# TM4C1294NCPDT register map
Vendor: Texas Instruments; File version: 2.2.0.295
CPU: CM4 r0p1, little endian, MPU, FPU, 3 interrupt priority bits
Registers are 32-bit, read-write, no defined reset value unless marked. A register's access mark holds for its fields unless they carry their own. Offsets are from the block's base; [hi:lo] are bit positions; {n}, {i} and the like mark numbered series; 'fields as' and 'values as' point back to an identical list.

## EPI0 — External Peripheral Interface (EPI0)
Base 0x400D0000
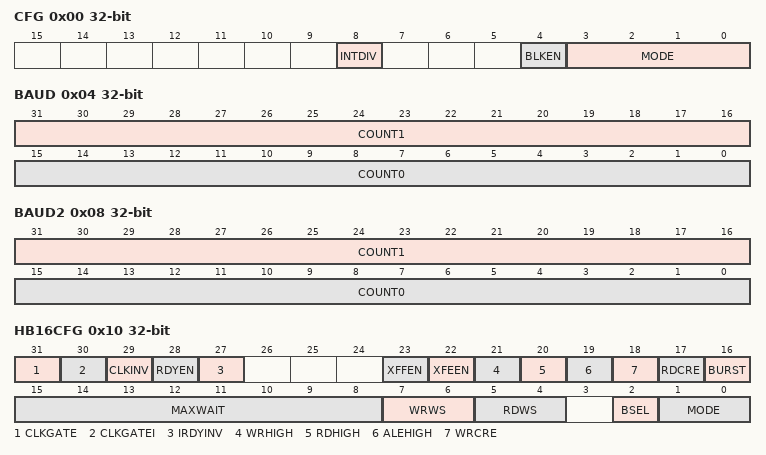
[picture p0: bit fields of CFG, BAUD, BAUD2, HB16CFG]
0x00 CFG
  [8] INTDIV — Integer Clock Divider Enable
  [4] BLKEN — Block Enable
  [3:0] MODE — Mode Select
    0=NONE (General Purpose); 1=SDRAM; 2=HB8 (8-Bit Host-Bus (HB8)); 3=HB16 (16-Bit Host-Bus (HB16))
0x04 BAUD
  [31:16] COUNT1 — Baud Rate Counter 1
  [15:0] COUNT0 — Baud Rate Counter 0
0x08 BAUD2
  [31:16] COUNT1 — CS3n Baud Rate Counter 1
  [15:0] COUNT0 — CS2n Baud Rate Counter 0
0x10 HB16CFG
  [31] CLKGATE — Clock Gated
  [30] CLKGATEI — Clock Gated Idle
  [29] CLKINV — Invert Output Clock Enable
  [28] RDYEN — Input Ready Enable
  [27] IRDYINV — Input Ready Invert
  [23] XFFEN — External FIFO FULL Enable
  [22] XFEEN — External FIFO EMPTY Enable
  [21] WRHIGH — WRITE Strobe Polarity
  [20] RDHIGH — READ Strobe Polarity
  [19] ALEHIGH — ALE Strobe Polarity
  [18] WRCRE — PSRAM Configuration Register
  [17] RDCRE — PSRAM Configuration Register
  [16] BURST — Burst Mode
  [15:8] MAXWAIT — Maximum Wait
  [7:6] WRWS — Write Wait States
    0=Active WRn is 2 EPI clocks; 1=Active WRn is 4 EPI clocks; 2=Active WRn is 6 EPI clocks; 3=Active WRn is 8 EPI clocks
  [5:4] RDWS — Read Wait States
    0=Active RDn is 2 EPI clocks; 1=Active RDn is 4 EPI clocks; 2=Active RDn is 6 EPI clocks; 3=Active RDn is 8 EPI clocks
  [2] BSEL — Byte Select Configuration
  [1:0] MODE — Host Bus Sub-Mode
    0=ADMUX (ADMUX - AD[15:0]); 1=ADNMUX (ADNONMUX - D[15:0]); 2=SRAM (Continuous Read - D[15:0]); 3=XFIFO (XFIFO - D[15:0])
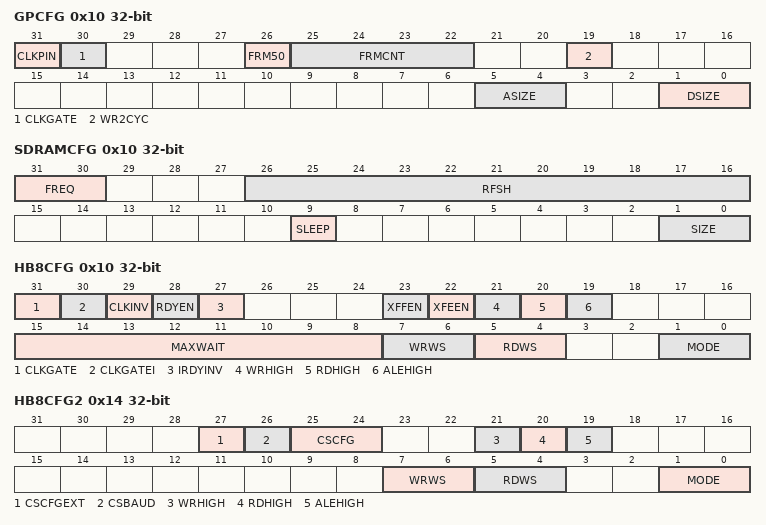
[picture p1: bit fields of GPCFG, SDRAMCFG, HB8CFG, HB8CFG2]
0x10 GPCFG
  [31] CLKPIN — Clock Pin
  [30] CLKGATE — Clock Gated
  [26] FRM50 — 50/50 Frame
  [25:22] FRMCNT — Frame Count
  [19] WR2CYC — 2-Cycle Writes
  [5:4] ASIZE — Address Bus Size
    0=NONE (No address); 1=4BIT (Up to 4 bits wide); 2=12BIT (Up to 12 bits wide. This size); 3=20BIT (Up to 20 bits wide. This size)
  [1:0] DSIZE — Size of Data Bus
    0=4BIT (8 Bits Wide (EPI0S0 to EPI0S7)); 1=16BIT (16 Bits Wide (EPI0S0 to EPI0S15)); 2=24BIT (24 Bits Wide (EPI0S0 to EPI0S23)); 3=32BIT (32 Bits Wide (EPI0S0 to EPI0S31))
0x10 SDRAMCFG
  [31:30] FREQ — EPI Frequency Range
    0=NONE (0 - 15 MHz); 1=15MHZ (15 - 30 MHz); 2=30MHZ (30 - 50 MHz)
  [26:16] RFSH — Refresh Counter
  [9] SLEEP — Sleep Mode
  [1:0] SIZE — Size of SDRAM
    0=8MB (64 megabits (8MB)); 1=16MB (128 megabits (16MB)); 2=32MB (256 megabits (32MB)); 3=64MB (512 megabits (64MB))
0x10 HB8CFG
  [31] CLKGATE — Clock Gated
  [30] CLKGATEI — Clock Gated when Idle
  [29] CLKINV — Invert Output Clock Enable
  [28] RDYEN — Input Ready Enable
  [27] IRDYINV — Input Ready Invert
  [23] XFFEN — External FIFO FULL Enable
  [22] XFEEN — External FIFO EMPTY Enable
  [21] WRHIGH — WRITE Strobe Polarity
  [20] RDHIGH — READ Strobe Polarity
  [19] ALEHIGH — ALE Strobe Polarity
  [15:8] MAXWAIT — Maximum Wait
  [7:6] WRWS — Write Wait States
    values as HB16CFG.WRWS
  [5:4] RDWS — Read Wait States
    values as HB16CFG.RDWS
  [1:0] MODE — Host Bus Sub-Mode
    0=MUX (ADMUX - AD[7:0]); 1=NMUX (ADNONMUX - D[7:0]); 2=SRAM (Continuous Read - D[7:0]); 3=FIFO (XFIFO - D[7:0])
0x14 HB8CFG2
  [27] CSCFGEXT — Chip Select Extended
  [26] CSBAUD — Chip Select Baud Rate and
  [25:24] CSCFG — Chip Select Configuration
    0=ALE (ALE Configuration); 1=CS (CSn Configuration); 2=DCS (Dual CSn Configuration); 3=ADCS (ALE with Dual CSn Configuration)
  [21] WRHIGH — CS1n WRITE Strobe Polarity
  [20] RDHIGH — CS1n READ Strobe Polarity
  [19] ALEHIGH — CS1n ALE Strobe Polarity
  [7:6] WRWS — CS1n Write Wait States
    values as HB16CFG.WRWS
  [5:4] RDWS — CS1n Read Wait States
    values as HB16CFG.RDWS
  [1:0] MODE — CS1n Host Bus Sub-Mode
    0=ADMUX (ADMUX - AD[7:0]); 1=AD (ADNONMUX - D[7:0])
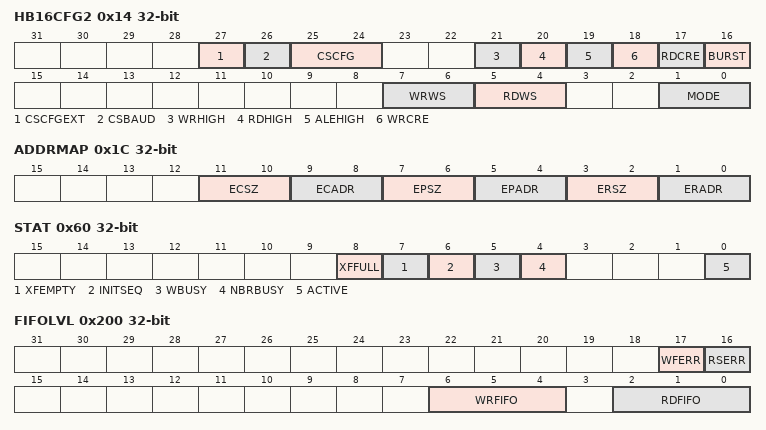
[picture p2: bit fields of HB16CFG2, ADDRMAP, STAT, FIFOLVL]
0x14 HB16CFG2
  [27] CSCFGEXT — Chip Select Extended
  [26] CSBAUD — Chip Select Baud Rate and
  [25:24] CSCFG — Chip Select Configuration
    values as HB8CFG2.CSCFG
  [21] WRHIGH — CS1n WRITE Strobe Polarity
  [20] RDHIGH — CS1n READ Strobe Polarity
  [19] ALEHIGH — CS1n ALE Strobe Polarity
  [18] WRCRE — CS1n PSRAM Configuration
  [17] RDCRE — CS1n PSRAM Configuration
  [16] BURST — CS1n Burst Mode
  [7:6] WRWS — CS1n Write Wait States
    values as HB16CFG.WRWS
  [5:4] RDWS — CS1n Read Wait States
    values as HB16CFG.RDWS
  [1:0] MODE — CS1n Host Bus Sub-Mode
    0=ADMUX (ADMUX - AD[15:0]); 1=AD (ADNONMUX - D[15:0])
0x1C ADDRMAP
  [11:10] ECSZ — External Code Size
    0=256B (256 bytes; lower address range:); 1=64KB (64 KB; lower address range:); 2=16MB (16 MB; lower address range:); 3=256MB (256MB; lower address range:)
  [9:8] ECADR — External Code Address
    0=NONE (Not mapped); 1=At 0x1000.0000
  [7:6] EPSZ — External Peripheral Size
    0=256B (256 bytes; lower address range:); 1=64KB (64 KB; lower address range:); 2=16MB (16 MB; lower address range:); 3=256MB (256 MB; lower address range:)
  [5:4] EPADR — External Peripheral Address
    0=NONE (Not mapped); 1=A000 (At 0xA000.0000); 2=C000 (At 0xC000.0000); 3=HBQS (Only to be used with Host Bus)
  [3:2] ERSZ — External RAM Size
    values as EPSZ
  [1:0] ERADR — External RAM Address
    0=NONE (Not mapped); 1=At 0x6000.0000; 2=At 0x8000.0000; 3=HBQS (Only to be used with Host Bus)
0x20 RSIZE0
  [1:0] SIZE — Current Size
    1=8BIT (Byte (8 bits)); 2=16BIT (Half-word (16 bits)); 3=32BIT (Word (32 bits))
0x24 RADDR0
  [31:0] ADDR — Current Address
0x28 RPSTD0
  [12:0] POSTCNT — Post Count
0x30 RSIZE1
  fields as RSIZE0
0x34 RADDR1
  [31:0] ADDR — Current Address
0x38 RPSTD1
  [12:0] POSTCNT — Post Count
0x60 STAT
  [8] XFFULL — External FIFO Full
  [7] XFEMPTY — External FIFO Empty
  [6] INITSEQ — Initialization Sequence
  [5] WBUSY — Write Busy
  [4] NBRBUSY — Non-Blocking Read Busy
  [0] ACTIVE
0x6C RFIFOCNT
  [3:0] COUNT — FIFO Count
{0x70+4i} READFIFO{i} read-modifies (i=0..7)
  [31:0] DATA — Reads Data
0x200 FIFOLVL
  [17] WFERR — Write Full Error
  [16] RSERR — Read Stall Error
  [6:4] WRFIFO — Write FIFO
    0=EMPT (Interrupt is triggered while); 2=Interrupt is triggered until; 3=Interrupt is triggered until; 4=NFULL (Trigger interrupt when WRFIFO is)
  [2:0] RDFIFO — Read FIFO
    1=Trigger when there are 1 or more; 2=Trigger when there are 2 or more; 3=Trigger when there are 4 or more; 4=Trigger when there are 6 or more; 5=Trigger when there are 7 or more; 6=Trigger when there are 8 entries
0x204 WFIFOCNT
  [2:0] WTAV — Available Write Transactions
0x208 DMATXCNT
  [15:0] TXCNT — DMA Count
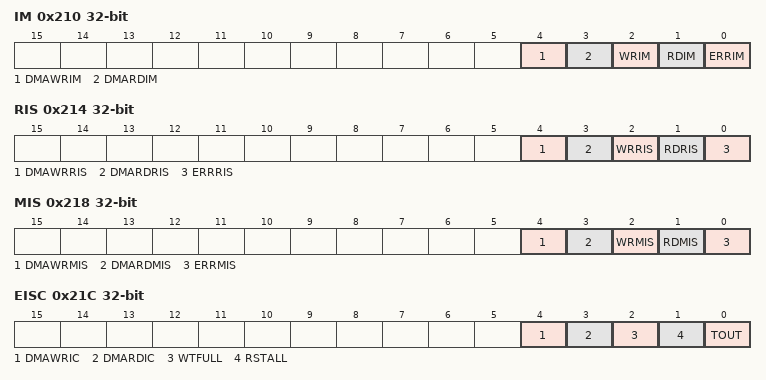
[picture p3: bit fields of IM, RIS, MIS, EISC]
0x210 IM
  [4] DMAWRIM — Write uDMA Interrupt Mask
  [3] DMARDIM — Read uDMA Interrupt Mask
  [2] WRIM — Write FIFO Empty Interrupt Mask
  [1] RDIM — Read FIFO Full Interrupt Mask
  [0] ERRIM — Error Interrupt Mask
0x214 RIS
  [4] DMAWRRIS — Write uDMA Raw Interrupt Status
  [3] DMARDRIS — Read uDMA Raw Interrupt Status
  [2] WRRIS — Write Raw Interrupt Status
  [1] RDRIS — Read Raw Interrupt Status
  [0] ERRRIS — Error Raw Interrupt Status
0x218 MIS
  [4] DMAWRMIS — Write uDMA Masked Interrupt
  [3] DMARDMIS — Read uDMA Masked Interrupt
  [2] WRMIS — Write Masked Interrupt Status
  [1] RDMIS — Read Masked Interrupt Status
  [0] ERRMIS — Error Masked Interrupt Status
0x21C EISC
  [4] DMAWRIC — Write uDMA Interrupt Clear
  [3] DMARDIC — Read uDMA Interrupt Clear
  [2] WTFULL — Write FIFO Full Error
  [1] RSTALL — Read Stalled Error
  [0] TOUT — Timeout Error
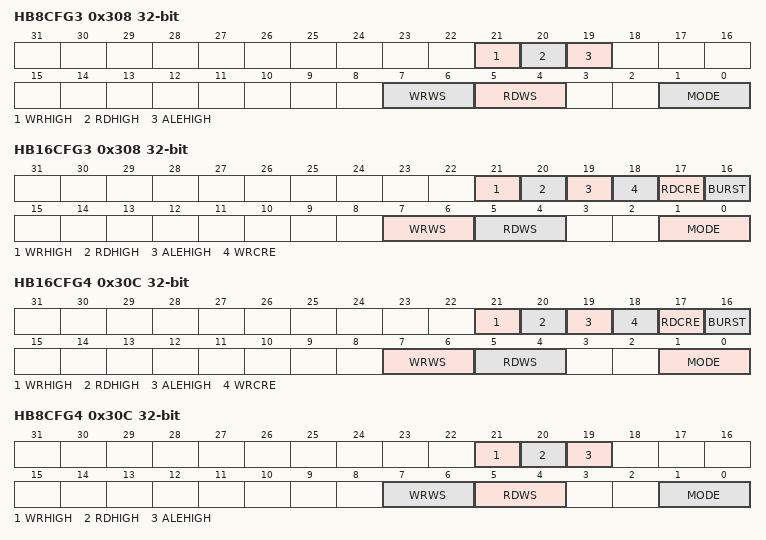
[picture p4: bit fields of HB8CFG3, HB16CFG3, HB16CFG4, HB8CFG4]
0x308 HB8CFG3
  [21] WRHIGH — CS2n WRITE Strobe Polarity
  [20] RDHIGH — CS2n READ Strobe Polarity
  [19] ALEHIGH — CS2n ALE Strobe Polarity
  [7:6] WRWS — CS2n Write Wait States
    values as HB16CFG.WRWS
  [5:4] RDWS — CS2n Read Wait States
    values as HB16CFG.RDWS
  [1:0] MODE — CS2n Host Bus Sub-Mode
    0=ADMUX (ADMUX - AD[7:0]); 1=AD (ADNONMUX - D[7:0])
0x308 HB16CFG3
  [21] WRHIGH — CS2n WRITE Strobe Polarity
  [20] RDHIGH — CS2n READ Strobe Polarity
  [19] ALEHIGH — CS2n ALE Strobe Polarity
  [18] WRCRE — CS2n PSRAM Configuration
  [17] RDCRE — CS2n PSRAM Configuration
  [16] BURST — CS2n Burst Mode
  [7:6] WRWS — CS2n Write Wait States
    values as HB16CFG.WRWS
  [5:4] RDWS — CS2n Read Wait States
    values as HB16CFG.RDWS
  [1:0] MODE — CS2n Host Bus Sub-Mode
    0=ADMUX (ADMUX - AD[15:0]); 1=AD (ADNONMUX - D[15:0])
0x30C HB16CFG4
  [21] WRHIGH — CS3n WRITE Strobe Polarity
  [20] RDHIGH — CS3n READ Strobe Polarity
  [19] ALEHIGH — CS3n ALE Strobe Polarity
  [18] WRCRE — CS3n PSRAM Configuration
  [17] RDCRE — CS3n PSRAM Configuration
  [16] BURST — CS3n Burst Mode
  [7:6] WRWS — CS3n Write Wait States
    values as HB16CFG.WRWS
  [5:4] RDWS — CS3n Read Wait States
    values as HB16CFG.RDWS
  [1:0] MODE — CS3n Host Bus Sub-Mode
    0=ADMUX (ADMUX - AD[15:0]); 1=AD (ADNONMUX - D[15:0])
0x30C HB8CFG4
  [21] WRHIGH — CS3n WRITE Strobe Polarity
  [20] RDHIGH — CS2n READ Strobe Polarity
  [19] ALEHIGH — CS3n ALE Strobe Polarity
  [7:6] WRWS — CS3n Write Wait States
    values as HB16CFG.WRWS
  [5:4] RDWS — CS3n Read Wait States
    values as HB16CFG.RDWS
  [1:0] MODE — CS3n Host Bus Sub-Mode
    0=ADMUX (ADMUX - AD[7:0]); 1=AD (ADNONMUX - D[7:0])
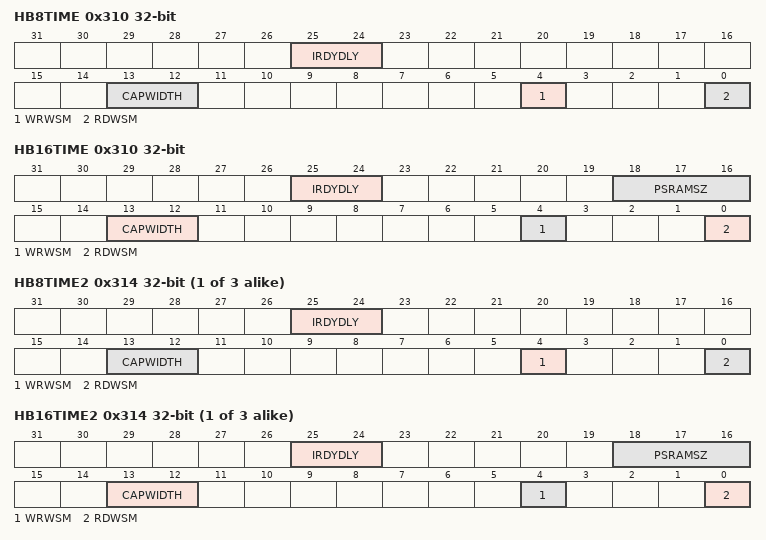
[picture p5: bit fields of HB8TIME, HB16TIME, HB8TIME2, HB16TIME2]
0x310 HB8TIME
  [25:24] IRDYDLY — CS0n Input Ready Delay
  [13:12] CAPWIDTH — CS0n Inter-transfer Capture
  [4] WRWSM — Write Wait State Minus One
  [0] RDWSM — Read Wait State Minus One
0x310 HB16TIME
  [25:24] IRDYDLY — CS0n Input Ready Delay
  [18:16] PSRAMSZ — PSRAM Row Size
    0=No row size limitation; 1=128B; 2=256B; 3=512B; 4=1KB (1024 B); 5=2KB (2048 B); 6=4KB (4096 B); 7=8KB (8192 B)
  [13:12] CAPWIDTH — CS0n Inter-transfer Capture
  [4] WRWSM — Write Wait State Minus One
  [0] RDWSM — Read Wait State Minus One
{0x30C+4i} HB8TIME{i} (i=2..4)
  [25:24] IRDYDLY — CS{i-1}n Input Ready Delay
  [13:12] CAPWIDTH — CS{i-1}n Inter-transfer Capture
  [4] WRWSM — CS{i-1}n Write Wait State Minus One
  [0] RDWSM — CS{i-1}n Read Wait State Minus One
{0x30C+4i} HB16TIME{i} (i=2..4)
  [25:24] IRDYDLY — CS{i-1}n Input Ready Delay
  [18:16] PSRAMSZ — PSRAM Row Size
    values as HB16TIME.PSRAMSZ
  [13:12] CAPWIDTH — CS{i-1}n Inter-transfer Capture
  [4] WRWSM — CS{i-1}n Write Wait State Minus One
  [0] RDWSM — CS{i-1}n Read Wait State Minus One
0x360 HBPSRAM
  [20:0] CR — PSRAM Config Register
